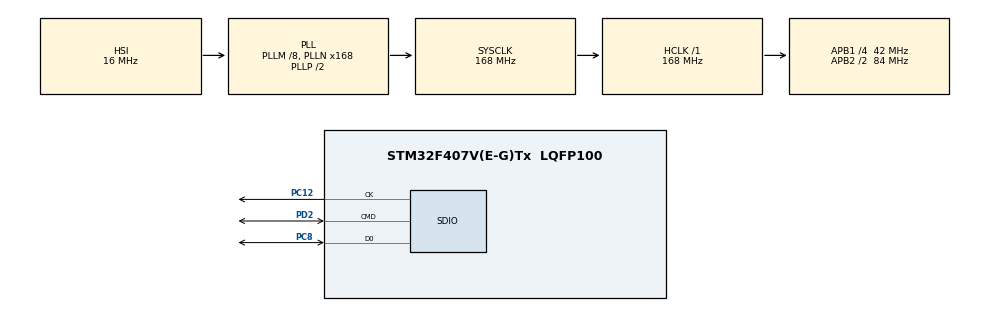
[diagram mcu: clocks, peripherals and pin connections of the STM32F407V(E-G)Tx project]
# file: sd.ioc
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Mcu.Family=STM32F4
Mcu.Name=STM32F407V(E-G)Tx
Mcu.Package=LQFP100
NVIC.PriorityGroup=NVIC_PRIORITYGROUP_4
PA13.Mode=Serial_Wire
PA13.Signal=SYS_JTMS-SWDIO
PA14.Mode=Serial_Wire
PA14.Signal=SYS_JTCK-SWCLK
PC12.Mode=SD_1_bit
PC12.Signal=SDIO_CK
PC8.Mode=SD_1_bit
PC8.Signal=SDIO_D0
PD2.Mode=SD_1_bit
PD2.Signal=SDIO_CMD
PH0-OSC_IN.Mode=HSE-External-Oscillator
PH0-OSC_IN.Signal=RCC_OSC_IN
PH1-OSC_OUT.Mode=HSE-External-Oscillator
PH1-OSC_OUT.Signal=RCC_OSC_OUT
ProjectManager.HeapSize=0x200
ProjectManager.StackSize=0x400
ProjectManager.TargetToolchain=MDK-ARM V5
RCC.48MHZClocksFreq_Value=48000000
RCC.AHBFreq_Value=168000000
RCC.APB1CLKDivider=RCC_HCLK_DIV4
RCC.APB1Freq_Value=42000000
RCC.APB1TimFreq_Value=84000000
RCC.APB2CLKDivider=RCC_HCLK_DIV2
RCC.APB2Freq_Value=84000000
RCC.APB2TimFreq_Value=168000000
RCC.CortexFreq_Value=168000000
RCC.HCLKFreq_Value=168000000
RCC.HSE_VALUE=25000000
RCC.HSI_VALUE=16000000
RCC.PLLM=8
RCC.PLLN=168
RCC.PLLQ=7
RCC.SYSCLKFreq_VALUE=168000000
RCC.SYSCLKSource=RCC_SYSCLKSOURCE_PLLCLK
RCC.VCOOutputFreq_Value=336000000
SDIO.BusWide=SDIO_BUS_WIDE_1B
VP_FATFS_VS_SDIO.Mode=SDIO
board=sd

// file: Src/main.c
/**
  ******************************************************************************
  * File Name          : main.c
  * Description        : Main program body
  ******************************************************************************
  *
  * COPYRIGHT(c) 2016 STMicroelectronics
  *
  * Redistribution and use in source and binary forms, with or without modification,
  * are permitted provided that the following conditions are met:
  *   1. Redistributions of source code must retain the above copyright notice,
  *      this list of conditions and the following disclaimer.
  *   2. Redistributions in binary form must reproduce the above copyright notice,
  *      this list of conditions and the following disclaimer in the documentation
  *      and/or other materials provided with the distribution.
  *   3. Neither the name of STMicroelectronics nor the names of its contributors
  *      may be used to endorse or promote products derived from this software
  *      without specific prior written permission.
  *
  * THIS SOFTWARE IS PROVIDED BY THE COPYRIGHT HOLDERS AND CONTRIBUTORS "AS IS"
  * AND ANY EXPRESS OR IMPLIED WARRANTIES, INCLUDING, BUT NOT LIMITED TO, THE
  * IMPLIED WARRANTIES OF MERCHANTABILITY AND FITNESS FOR A PARTICULAR PURPOSE ARE
  * DISCLAIMED. IN NO EVENT SHALL THE COPYRIGHT HOLDER OR CONTRIBUTORS BE LIABLE
  * FOR ANY DIRECT, INDIRECT, INCIDENTAL, SPECIAL, EXEMPLARY, OR CONSEQUENTIAL
  * DAMAGES (INCLUDING, BUT NOT LIMITED TO, PROCUREMENT OF SUBSTITUTE GOODS OR
  * SERVICES; LOSS OF USE, DATA, OR PROFITS; OR BUSINESS INTERRUPTION) HOWEVER
  * CAUSED AND ON ANY THEORY OF LIABILITY, WHETHER IN CONTRACT, STRICT LIABILITY,
  * OR TORT (INCLUDING NEGLIGENCE OR OTHERWISE) ARISING IN ANY WAY OUT OF THE USE
  * OF THIS SOFTWARE, EVEN IF ADVISED OF THE POSSIBILITY OF SUCH DAMAGE.
  *
  ******************************************************************************
  */
#include "stm32f4xx_hal.h"
#include "fatfs.h"

SD_HandleTypeDef hsd;
HAL_SD_CardInfoTypedef SDCardInfo;

/* USER CODE BEGIN PV */
/* Private variables ---------------------------------------------------------*/
FRESULT res;
FIL myFile;

/* USER CODE END PV */

void SystemClock_Config(void);
void Error_Handler(void);
static void MX_GPIO_Init(void);
static void MX_SDIO_SD_Init(void);

/* USER CODE BEGIN PFP */
/* Private function prototypes -----------------------------------------------*/

/* USER CODE END PFP */

int main(void)
{

  /* MCU Configuration----------------------------------------------------------*/

  /* Reset of all peripherals, Initializes the Flash interface and the Systick. */
  HAL_Init();

  /* Configure the system clock */
  SystemClock_Config();

  /* Initialize all configured peripherals */
  MX_GPIO_Init();
  MX_SDIO_SD_Init();
  MX_FATFS_Init();

  /* Infinite loop */
  while (1)
  {

  }

}

/** System Clock Configuration
*/
void SystemClock_Config(void)
{

  RCC_OscInitTypeDef RCC_OscInitStruct;
  RCC_ClkInitTypeDef RCC_ClkInitStruct;

  __HAL_RCC_PWR_CLK_ENABLE();

  __HAL_PWR_VOLTAGESCALING_CONFIG(PWR_REGULATOR_VOLTAGE_SCALE1);

  RCC_OscInitStruct.OscillatorType = RCC_OSCILLATORTYPE_HSI;
  RCC_OscInitStruct.HSIState = RCC_HSI_ON;
  RCC_OscInitStruct.HSICalibrationValue = 16;
  RCC_OscInitStruct.PLL.PLLState = RCC_PLL_ON;
  RCC_OscInitStruct.PLL.PLLSource = RCC_PLLSOURCE_HSI;
  RCC_OscInitStruct.PLL.PLLM = 8;
  RCC_OscInitStruct.PLL.PLLN = 168;
  RCC_OscInitStruct.PLL.PLLP = RCC_PLLP_DIV2;
  RCC_OscInitStruct.PLL.PLLQ = 7;
  if (HAL_RCC_OscConfig(&RCC_OscInitStruct) != HAL_OK)
  {
    Error_Handler();
  }

  RCC_ClkInitStruct.ClockType = RCC_CLOCKTYPE_HCLK|RCC_CLOCKTYPE_SYSCLK
                              |RCC_CLOCKTYPE_PCLK1|RCC_CLOCKTYPE_PCLK2;
  RCC_ClkInitStruct.SYSCLKSource = RCC_SYSCLKSOURCE_PLLCLK;
  RCC_ClkInitStruct.AHBCLKDivider = RCC_SYSCLK_DIV1;
  RCC_ClkInitStruct.APB1CLKDivider = RCC_HCLK_DIV4;
  RCC_ClkInitStruct.APB2CLKDivider = RCC_HCLK_DIV2;
  if (HAL_RCC_ClockConfig(&RCC_ClkInitStruct, FLASH_LATENCY_5) != HAL_OK)
  {
    Error_Handler();
  }

  HAL_SYSTICK_Config(HAL_RCC_GetHCLKFreq()/1000);

  HAL_SYSTICK_CLKSourceConfig(SYSTICK_CLKSOURCE_HCLK);

  /* SysTick_IRQn interrupt configuration */
  HAL_NVIC_SetPriority(SysTick_IRQn, 0, 0);
}

/* SDIO init function */
static void MX_SDIO_SD_Init(void)
{

  hsd.Instance = SDIO;
  hsd.Init.ClockEdge = SDIO_CLOCK_EDGE_RISING;
  hsd.Init.ClockBypass = SDIO_CLOCK_BYPASS_DISABLE;
  hsd.Init.ClockPowerSave = SDIO_CLOCK_POWER_SAVE_DISABLE;
  hsd.Init.BusWide = SDIO_BUS_WIDE_1B;
  hsd.Init.HardwareFlowControl = SDIO_HARDWARE_FLOW_CONTROL_DISABLE;
  hsd.Init.ClockDiv = 0;

}

/** Configure pins as
        * Analog
        * Input
        * Output
        * EVENT_OUT
        * EXTI
*/
static void MX_GPIO_Init(void)
{

  /* GPIO Ports Clock Enable */
  __HAL_RCC_GPIOH_CLK_ENABLE();
  __HAL_RCC_GPIOC_CLK_ENABLE();
  __HAL_RCC_GPIOA_CLK_ENABLE();
  __HAL_RCC_GPIOD_CLK_ENABLE();

}

void Error_Handler(void)
{
  while(1)
  {
  }
}

/************************ (C) COPYRIGHT STMicroelectronics *****END OF FILE****/
